AUTOSAR XML (schema 00044)
package /E40_Platform_System_SystemPackage/Components
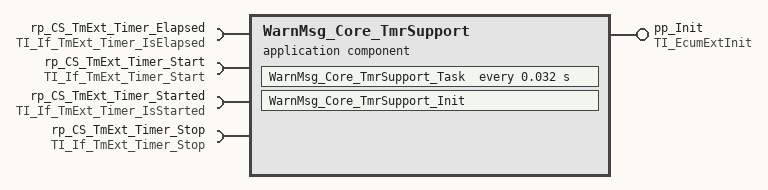
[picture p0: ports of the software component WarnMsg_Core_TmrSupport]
  application sw component type WarnMsg_Core_TmrSupport
    provide port pp_Init: server-com-spec{operation=Init, queue-length=1}, provided-interface=TI_EcumExtInit
    4 x require port:
      rp_CS_TmExt_Timer_Elapsed: client-com-spec=Timer_IsElapsed, required-interface=TI_If_TmExt_Timer_IsElapsed
      rp_CS_TmExt_Timer_Start: client-com-spec=Timer_Start, required-interface=TI_If_TmExt_Timer_Start
      rp_CS_TmExt_Timer_Started: client-com-spec=Timer_IsStarted, required-interface=TI_If_TmExt_Timer_IsStarted
      rp_CS_TmExt_Timer_Stop: client-com-spec=Timer_Stop, required-interface=TI_If_TmExt_Timer_Stop
    behavior IB_WarnMsg_Core_TmrSupport
      operation invoked event OIE_pp_Init_WarnMsg_Core_TmrSupport_InitTrigByInit: start-on-event=WarnMsg_Core_TmrSupport_Init, operation=pp_Init.Init
      timing event TEWarnMsg_Core_TmrSupport_Task: start-on-event=WarnMsg_Core_TmrSupport_Task, period=0.032
      port-api-options:
        enable-take-address=false, indirect-api=false, port=pp_Init
        enable-take-address=false, indirect-api=false, port=rp_CS_TmExt_Timer_Elapsed
        enable-take-address=false, indirect-api=false, port=rp_CS_TmExt_Timer_Start
        enable-take-address=false, indirect-api=false, port=rp_CS_TmExt_Timer_Started
        enable-take-address=false, indirect-api=false, port=rp_CS_TmExt_Timer_Stop
      runnable WarnMsg_Core_TmrSupport_Init: can-be-invoked-concurrently=true
      runnable WarnMsg_Core_TmrSupport_Task: can-be-invoked-concurrently=true
        4 x sync call:
          OA_rp_CS_TmExt_Timer_Elapsed_Timer_IsElapsed: operation=rp_CS_TmExt_Timer_Elapsed.Timer_IsElapsed
          OA_rp_CS_TmExt_Timer_Start_Timer_Start: operation=rp_CS_TmExt_Timer_Start.Timer_Start
          OA_rp_CS_TmExt_Timer_Started_Timer_IsStarted: operation=rp_CS_TmExt_Timer_Started.Timer_IsStarted
          OA_rp_CS_TmExt_Timer_Stop_Timer_Stop: operation=rp_CS_TmExt_Timer_Stop.Timer_Stop
  swc implementation IMPL_WarnMsg_Core_TmrSupport: behavior=IB_WarnMsg_Core_TmrSupport
